# EFR32BG21B020F768IM32 register map
Vendor: Silicon Labs; Series: EFR32; File version: D
Registers are 32-bit, read-write, reset 0x0 unless marked. A register's access mark holds for its fields unless they carry their own. Offsets are from the block's base; [hi:lo] are bit positions; 'fields as' and 'values as' point back to an identical list.

## DPLL0_NS — DPLL0_NS Registers
Base 0x5001C000
Same registers: DPLL0_S 0x4001C000
0x00 IPVERSION ro
  [31:0] IPVERSION — IP Version ID
0x04 EN
  [0] EN — Module Enable
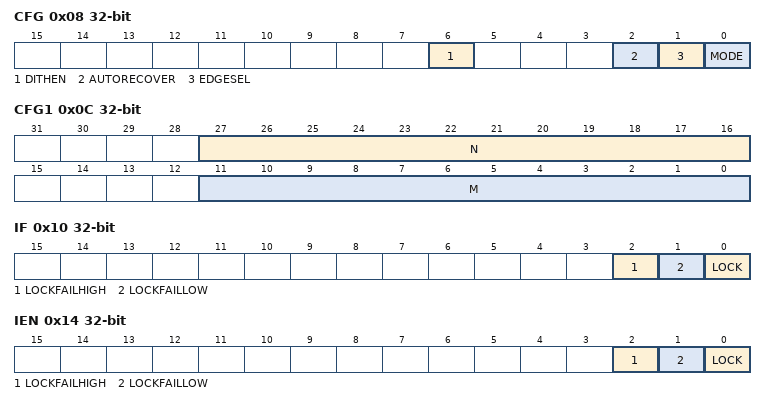
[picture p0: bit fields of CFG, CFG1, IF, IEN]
0x08 CFG
  [6] DITHEN — Dither Enable Control
  [2] AUTORECOVER — Automatic Recovery Control
  [1] EDGESEL — Reference Edge Select
  [0] MODE — Operating Mode Control
    0=FLL (Frequency Lock Mode); 1=PLL (Phase Lock Mode)
0x0C CFG1
  [27:16] N — Factor N
  [11:0] M — Factor M
0x10 IF
  [2] LOCKFAILHIGH — Lock Failure High Interrupt Flag
  [1] LOCKFAILLOW — Lock Failure Low Interrupt Flag
  [0] LOCK — Lock Interrupt Flag
0x14 IEN
  [2] LOCKFAILHIGH — LOCKFAILHIGH Interrupt Enable
  [1] LOCKFAILLOW — LOCKFAILLOW Interrupe Enable
  [0] LOCK — LOCK interrupt Enable
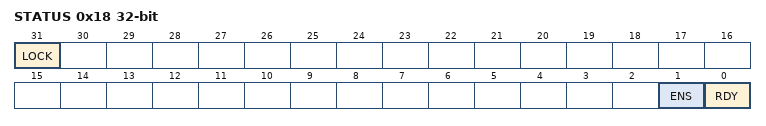
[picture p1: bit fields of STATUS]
0x18 STATUS ro
  [31] LOCK — Lock Status
    0=UNLOCKED (DPLL is unlocked); 1=LOCKED (DPLL is locked)
  [1] ENS — Enable Status
  [0] RDY — Ready Status
0x24 LOCK wo reset 0x7102
  [15:0] LOCKKEY
    0x7102=UNLOCK (Unlock code)

## FSRCO_NS — FSRCO_NS Registers
Base 0x50018000
Same registers: FSRCO_S 0x40018000
0x00 IPVERSION ro reset 0x1

## GPCRC_NS — GPCRC_NS Registers
Base 0x50088000
Same registers: GPCRC_S 0x40088000
0x00 IPVERSION ro
  [31:0] IPVERSION — IP Version ID
0x04 EN
  [0] EN — CRC Enable
    0=DISABLE (Disable CRC function. Reordering functions are still available. Only BITREVERSE and BYTEREVERSE bits are configurable in this mode.); 1=ENABLE (Writes to INPUTDATA registers will result in CRC operations.)
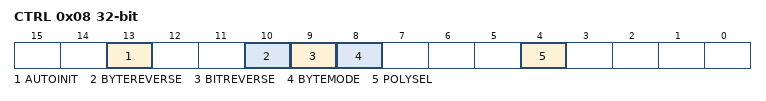
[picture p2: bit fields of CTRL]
0x08 CTRL
  [13] AUTOINIT — Auto Init Enable
  [10] BYTEREVERSE — Byte Reverse Mode
    0=NORMAL (No reverse: B3, B2, B1, B0); 1=REVERSED (Reverse byte order. For 32-bit: B0, B1, B2, B3; For 16-bit: 0, 0, B0, B1)
  [9] BITREVERSE — Byte-level Bit Reverse Enable
    0=NORMAL (No reverse); 1=REVERSED (Reverse bit order in each byte)
  [8] BYTEMODE — Byte Mode Enable
  [4] POLYSEL — Polynomial Select
    0=CRC32 (CRC-32 (0x04C11DB7) polynomial selected); 1=CRC16 (16-bit CRC programmable polynomial selected)
0x0C CMD wo
  [0] INIT — Initialization Enable
0x10 INIT
  [31:0] INIT — CRC Initialization Value
0x14 POLY
  [15:0] POLY — CRC Polynomial Value
0x18 INPUTDATA wo
  [31:0] INPUTDATA — Input Data for 32-bit
0x1C INPUTDATAHWORD wo
  [15:0] INPUTDATAHWORD — Input Data for 16-bit
0x20 INPUTDATABYTE wo
  [7:0] INPUTDATABYTE — Input Data for 8-bit
0x24 DATA ro
  [31:0] DATA — CRC Data Register
0x28 DATAREV ro
  [31:0] DATAREV — Data Reverse Value
0x2C DATABYTEREV ro
  [31:0] DATABYTEREV — Data Byte Reverse Value

## HFRCO0_NS — HFRCO0_NS Registers
Base 0x50010000
Same registers: HFRCO0_S 0x40010000, HFRCOEM23_S 0x4A014000, HFRCOEM23_NS 0x5A014000
0x00 IPVERSION ro
  [31:0] IPVERSION — IP Version ID
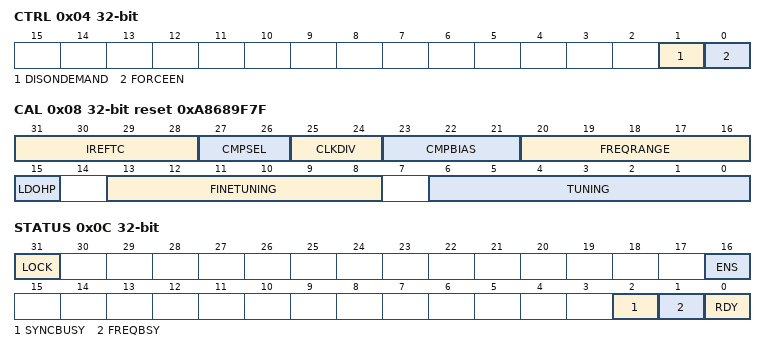
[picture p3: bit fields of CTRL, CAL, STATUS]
0x04 CTRL
  [1] DISONDEMAND — Disable On-demand
  [0] FORCEEN — Force Enable
0x08 CAL reset 0xA8689F7F
  [31:28] IREFTC — Tempco Trim on Comparator Current
  [27:26] CMPSEL — Comparator Load Select
  [25:24] CLKDIV — Locally Divide HFRCO Clock Output
    0=DIV1 (Divide by 1.); 1=DIV2 (Divide by 2.); 2=DIV4 (Divide by 4.)
  [23:21] CMPBIAS — Comparator Bias Current
  [20:16] FREQRANGE — Frequency Range
  [15] LDOHP — LDO High Power Mode
  [13:8] FINETUNING — Fine Tuning Value
  [6:0] TUNING — Tuning Value
0x0C STATUS ro
  [31] LOCK — Lock Status
    0=UNLOCKED; 1=LOCKED
  [16] ENS — Enable Status
  [2] SYNCBUSY — Synchronization Busy
  [1] FREQBSY — Frequency Updating Busy
  [0] RDY — Ready
0x10 IF
  [0] RDY — Ready Interrupt Flag
0x14 IEN
  [0] RDY — RDY Interrupt Enable
0x1C LOCK wo reset 0x8195
  [15:0] LOCKKEY
    0x8195=UNLOCK

## HFXO0_NS — HFXO0_NS Registers
Base 0x5000C000
Same registers: HFXO0_S 0x4000C000
0x00 IPVERSION ro reset 0x1
  [31:0] IPVERSION — IP Version ID
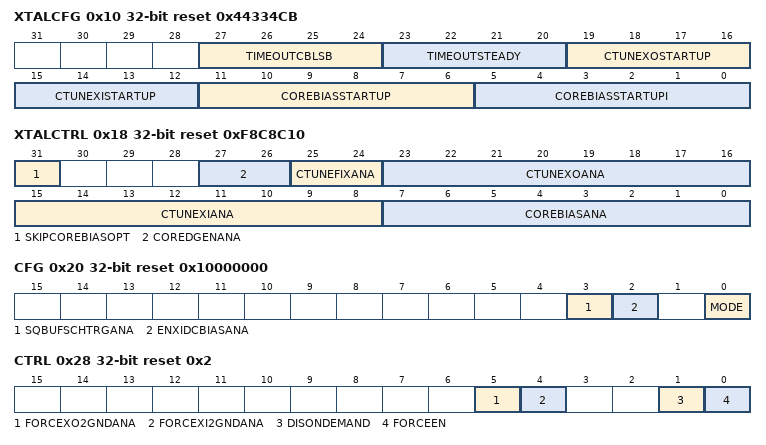
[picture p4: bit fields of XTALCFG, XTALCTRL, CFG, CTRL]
0x10 XTALCFG reset 0x44334CB
  [27:24] TIMEOUTCBLSB — Core Bias LSB Change Timeout
    0=T8US; 1=T20US; 2=T41US; 3=T62US; 4=T83US; 5=T104US; 6=T125US; 7=T166US; 8=T208US; 9=T250US; 10=T333US; 11=T416US; 12=T833US; 13=T1250US; 14=T2083US; 15=T3750US
  [23:20] TIMEOUTSTEADY — Steady State Timeout
    0=T16US; 1=T41US; 2=T83US; 3=T125US; 4=T166US; 5=T208US; 6=T250US; 7=T333US; 8=T416US; 9=T500US; 10=T666US; 11=T833US; 12=T1666US; 13=T2500US; 14=T4166US; 15=T7500US
  [19:16] CTUNEXOSTARTUP — Startup Tuning Capacitance on XO
  [15:12] CTUNEXISTARTUP — Startup Tuning Capacitance on XI
  [11:6] COREBIASSTARTUP — Startup Core Bias Current
  [5:0] COREBIASSTARTUPI — Intermediate Startup Core Bias Current
0x18 XTALCTRL reset 0xF8C8C10
  [31] SKIPCOREBIASOPT — Skip Core Bias Optimization
  [27:26] COREDGENANA — Core Degeneration
    0=NONE; 1=DGEN33; 2=DGEN50; 3=DGEN100
  [25:24] CTUNEFIXANA — Fixed Tuning Capacitance
    0=NONE; 1=XI; 2=XO; 3=BOTH
  [23:16] CTUNEXOANA — Tuning Capacitance on XO
  [15:8] CTUNEXIANA — Tuning Capacitance on XI
  [7:0] COREBIASANA — Core Bias Current
0x20 CFG reset 0x10000000
  [3] SQBUFSCHTRGANA — Squaring Buffer Schmitt Trigger
    0=DISABLE; 1=ENABLE
  [2] ENXIDCBIASANA — Enable XI Internal DC Bias
  [0] MODE — Crystal Oscillator Mode
    0=XTAL (crystal oscillator); 1=EXTCLK (external sinusoidal clock can be supplied on XI pin.)
0x28 CTRL reset 0x2
  [5] FORCEXO2GNDANA — Force XO Pin to Ground
    0=DISABLE (Disabled (not pulled)); 1=ENABLE (Enabled (pulled))
  [4] FORCEXI2GNDANA — Force XI Pin to Ground
    values as FORCEXO2GNDANA
  [1] DISONDEMAND — Disable On-demand Mode
  [0] FORCEEN — Force Enable
0x50 CMD wo
  [0] COREBIASOPT — Core Bias Optimizaton
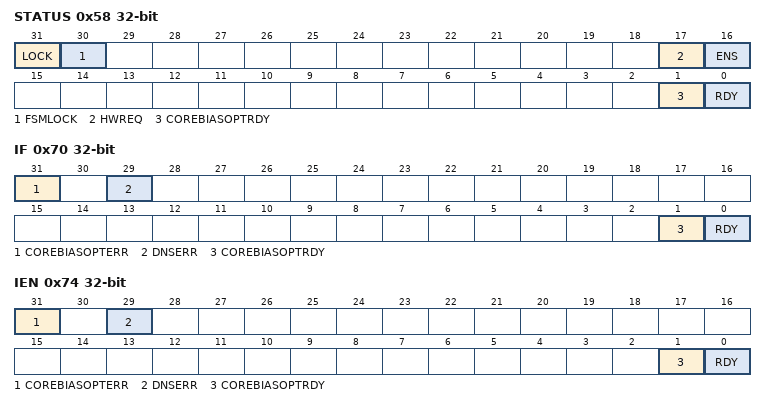
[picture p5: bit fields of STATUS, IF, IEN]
0x58 STATUS ro
  [31] LOCK — Configuration Lock Status
    0=UNLOCKED; 1=LOCKED
  [30] FSMLOCK — FSM Lock Status
    0=UNLOCKED; 1=LOCKED
  [17] HWREQ — Oscillator Requested by Hardware
  [16] ENS — Enabled Status
  [1] COREBIASOPTRDY — Core Bias Optimization Ready
  [0] RDY — Ready Status
0x70 IF
  [31] COREBIASOPTERR — Core Bias Optimization Error Interrupt
  [29] DNSERR — Did Not Start Error Interrupt
  [1] COREBIASOPTRDY — Core Bias Optimization Ready Interrupt
  [0] RDY — Ready Interrupt
0x74 IEN
  fields as IF
0x80 LOCK wo reset 0x580E
  [15:0] LOCKKEY — Configuration Lock Key
    0x580E=UNLOCK
